VERSION "oem_import_dbc_v0.1"

NS_ :

BS_:

BU_: AFC TeampoEVB TDA4VE AutoBox HMI_Simulation Vector__XXX

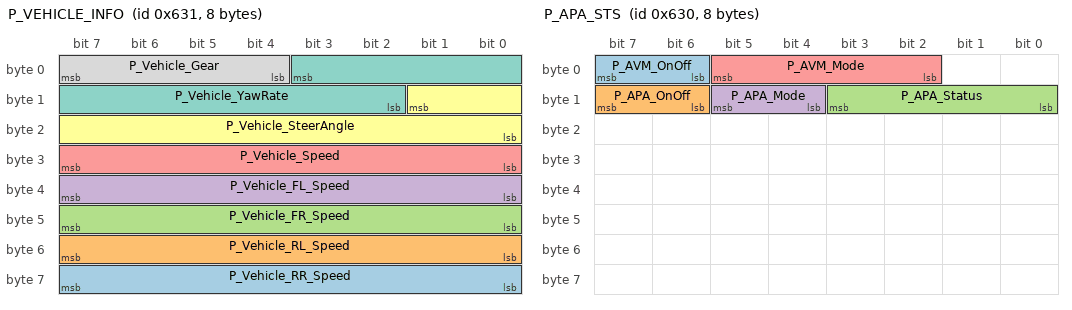
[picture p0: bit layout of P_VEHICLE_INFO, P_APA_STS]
BO_ 1585 P_VEHICLE_INFO: 8 AutoBox
 SG_ P_Vehicle_RR_Speed : 63|8@0+ (0.05,0) [0|12.7] "m/s" TDA4VE
 SG_ P_Vehicle_RL_Speed : 55|8@0+ (0.05,0) [0|12.7] "m/s" TDA4VE
 SG_ P_Vehicle_FR_Speed : 47|8@0+ (0.05,0) [0|12.7] "m/s" TDA4VE
 SG_ P_Vehicle_FL_Speed : 39|8@0+ (0.05,0) [0|12.7] "m/s" TDA4VE
 SG_ P_Vehicle_Speed : 31|8@0+ (0.05,0) [0|12.7] "m/s" TDA4VE
 SG_ P_Vehicle_SteerAngle : 9|10@0+ (4,-2048) [-2048|2044] "deg" TDA4VE
 SG_ P_Vehicle_YawRate : 3|10@0+ (0.2,-102.4) [-102.4|102.2] "deg/s" TDA4VE
 SG_ P_Vehicle_Gear : 7|4@0+ (1,0) [0|15] "" TDA4VE

BO_ 1584 P_APA_STS: 8 AutoBox
 SG_ P_AVM_OnOff : 7|2@0+ (1,0) [0|3] "" Vector__XXX
 SG_ P_APA_OnOff : 15|2@0+ (1,0) [0|3] "" Vector__XXX
 SG_ P_APA_Status : 11|4@0+ (1,0) [0|15] "" TDA4VE
 SG_ P_APA_Mode : 13|2@0+ (1,0) [0|3] "" TDA4VE
 SG_ P_AVM_Mode : 5|4@0+ (1,0) [0|15] "" TDA4VE

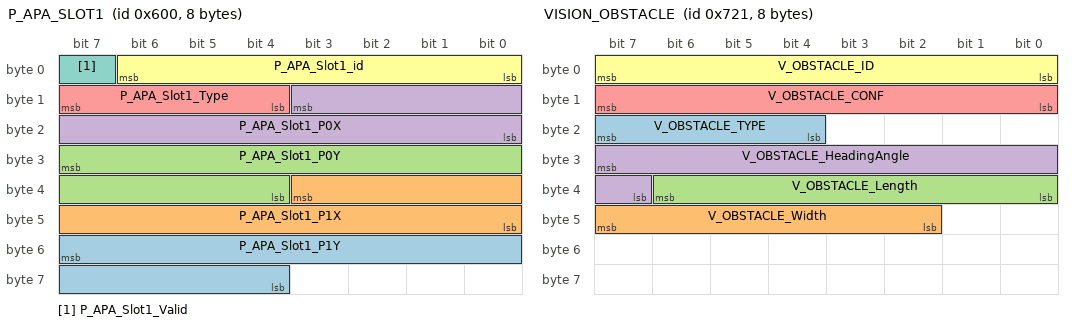
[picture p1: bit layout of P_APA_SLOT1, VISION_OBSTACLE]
BO_ 1536 P_APA_SLOT1: 8 TDA4VE
 SG_ P_APA_Slot1_P1Y : 55|12@0+ (0.01,-20.48) [-20.48|20.47] "m" AutoBox
 SG_ P_APA_Slot1_P1X : 35|12@0+ (0.01,-20.48) [-20.48|20.47] "m" AutoBox
 SG_ P_APA_Slot1_P0Y : 31|12@0+ (0.01,-20.48) [-20.48|20.47] "m" AutoBox
 SG_ P_APA_Slot1_P0X : 11|12@0+ (0.01,-20.48) [-20.48|20.47] "m" AutoBox
 SG_ P_APA_Slot1_Type : 15|4@0+ (1,0) [0|15] "" AutoBox
 SG_ P_APA_Slot1_id : 6|7@0+ (1,0) [0|127] "" AutoBox
 SG_ P_APA_Slot1_Valid : 7|1@0+ (1,0) [0|1] "" AutoBox

BO_ 1825 VISION_OBSTACLE: 8 TDA4VE
 SG_ V_OBSTACLE_TYPE : 23|4@0+ (1,0) [0|15] "" AFC
 SG_ V_OBSTACLE_Width : 47|6@0+ (0.1,0) [0|6.3] "m" AFC
 SG_ V_OBSTACLE_Length : 38|7@0+ (0.1,0) [0|12.7] "m" AFC
 SG_ V_OBSTACLE_HeadingAngle : 31|9@0+ (1,-256) [-256|255] "deg" AFC
 SG_ V_OBSTACLE_CONF : 15|8@0+ (0.5,0) [0|100] "" AFC
 SG_ V_OBSTACLE_ID : 7|8@0+ (1,0) [0|255] "" AFC

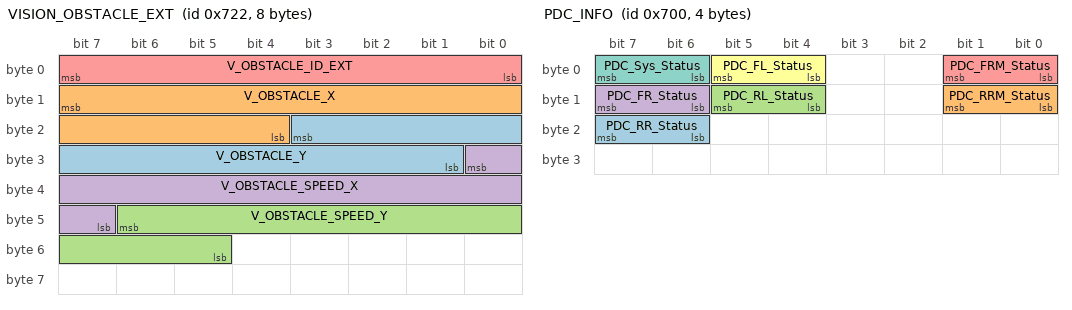
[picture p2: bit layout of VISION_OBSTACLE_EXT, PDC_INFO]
BO_ 1826 VISION_OBSTACLE_EXT: 8 TDA4VE
 SG_ V_OBSTACLE_Y : 19|11@0+ (0.1,-102.4) [-102.4|102.3] "m" AFC
 SG_ V_OBSTACLE_X : 15|12@0+ (0.1,-204.8) [-204.8|204.7] "m" AFC
 SG_ V_OBSTACLE_SPEED_Y : 46|10@0+ (0.1,-51.2) [-51.2|51.1] "m/s" AFC
 SG_ V_OBSTACLE_SPEED_X : 24|10@0+ (0.1,-51.2) [-51.2|51.1] "m/s" AFC
 SG_ V_OBSTACLE_ID_EXT : 7|8@0+ (1,0) [0|255] "" AFC

BO_ 1792 PDC_INFO: 4 AutoBox
 SG_ PDC_RR_Status : 23|2@0+ (1,0) [0|3] "" HMI_Simulation
 SG_ PDC_RRM_Status : 9|2@0+ (1,0) [0|3] "" HMI_Simulation
 SG_ PDC_RL_Status : 13|2@0+ (1,0) [0|3] "" HMI_Simulation
 SG_ PDC_FR_Status : 15|2@0+ (1,0) [0|3] "" HMI_Simulation
 SG_ PDC_FRM_Status : 1|2@0+ (1,0) [0|3] "" HMI_Simulation
 SG_ PDC_FL_Status : 5|2@0+ (1,0) [0|3] "" HMI_Simulation
 SG_ PDC_Sys_Status : 7|2@0+ (1,0) [0|3] "" HMI_Simulation

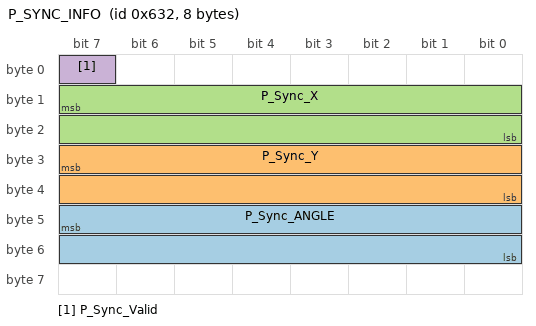
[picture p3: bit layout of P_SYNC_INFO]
BO_ 1586 P_SYNC_INFO: 8 AutoBox
 SG_ P_Sync_ANGLE : 47|16@0+ (0.0001,-3.2768) [-3.2768|3.2767] "rad" TDA4VE
 SG_ P_Sync_Y : 31|16@0+ (0.01,-327.68) [-327.68|327.67] "m" TDA4VE
 SG_ P_Sync_X : 15|16@0+ (0.01,-327.68) [-327.68|327.67] "m" TDA4VE
 SG_ P_Sync_Valid : 7|1@0+ (1,0) [0|1] "" TDA4VE
